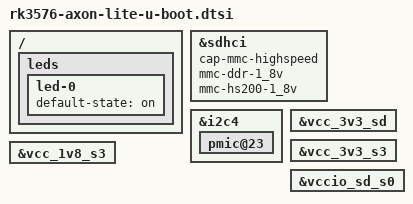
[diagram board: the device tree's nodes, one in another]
// SPDX-License-Identifier: GPL-2.0+
/*
 * Copyright (C) 2026 Hrushiraj Gandhi <hrushirajg23@gmail.com>
 */

#include "rk3576-u-boot.dtsi"

/ {
	leds {
		led-0 {
			default-state = "on";
		};
	};
};

&sdhci {
	cap-mmc-highspeed;
	mmc-ddr-1_8v;
	mmc-hs200-1_8v;
};

&i2c4 {
	bootph-all;
	pmic@23 {
		bootph-all;
	};
};

&vcc_3v3_sd {
	bootph-all;
};

&vcc_3v3_s3 {
	bootph-all;
};

&vcc_1v8_s3 {
	bootph-all;
};

&vccio_sd_s0 {
	bootph-all;
};

